# PIC32MZ2048EFM144 register map
Registers are 32-bit, access not given, reset 0x0 unless marked. A register's access mark holds for its fields unless they carry their own. Offsets are from the block's base; [hi:lo] are bit positions; {n}, {i} and the like mark numbered series; 'fields as' and 'values as' point back to an identical list.

## PORTG — PORTG peripheral
Base 0xBF860600
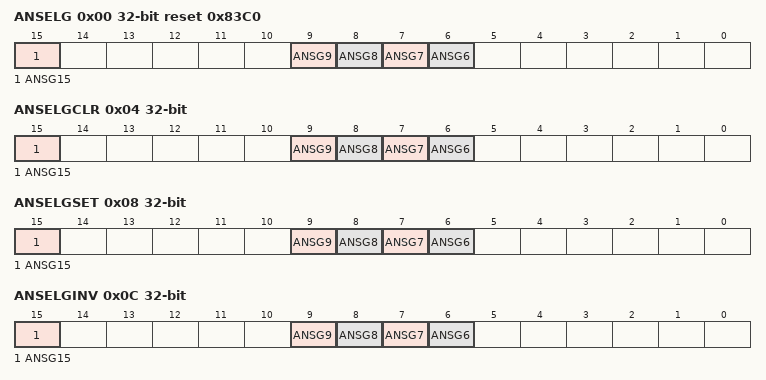
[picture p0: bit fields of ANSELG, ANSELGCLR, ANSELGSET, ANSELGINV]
0x00 ANSELG reset 0x83C0
  [15] ANSG15, [n] ANSG{n} (n=6..9)
0x04 ANSELGCLR
  [15] ANSG15, [n] ANSG{n} (n=6..9)
0x08 ANSELGSET
  [15] ANSG15, [n] ANSG{n} (n=6..9)
0x0C ANSELGINV
  [15] ANSG15, [n] ANSG{n} (n=6..9)
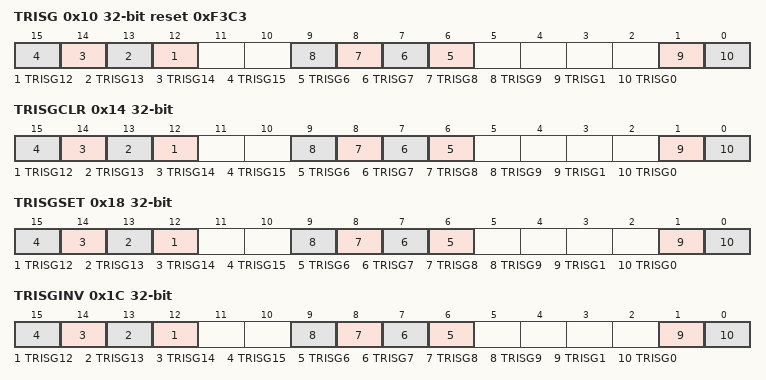
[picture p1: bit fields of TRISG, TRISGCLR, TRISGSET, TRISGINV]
0x10 TRISG reset 0xF3C3
  [n] TRISG{n} (n=12..15), [n] TRISG{n} (n=6..9), [1] TRISG1, [0] TRISG0
0x14 TRISGCLR
  fields as TRISG
0x18 TRISGSET
  fields as TRISG
0x1C TRISGINV
  fields as TRISG
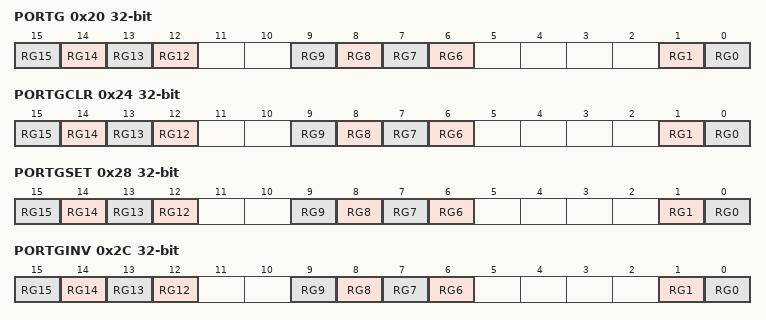
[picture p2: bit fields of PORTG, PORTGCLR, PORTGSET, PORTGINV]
0x20 PORTG
  [n] RG{n} (n=12..15), [n] RG{n} (n=6..9), [1] RG1, [0] RG0
0x24 PORTGCLR
  [n] RG{n} (n=12..15), [n] RG{n} (n=6..9), [1] RG1, [0] RG0
0x28 PORTGSET
  [n] RG{n} (n=12..15), [n] RG{n} (n=6..9), [1] RG1, [0] RG0
0x2C PORTGINV
  [n] RG{n} (n=12..15), [n] RG{n} (n=6..9), [1] RG1, [0] RG0
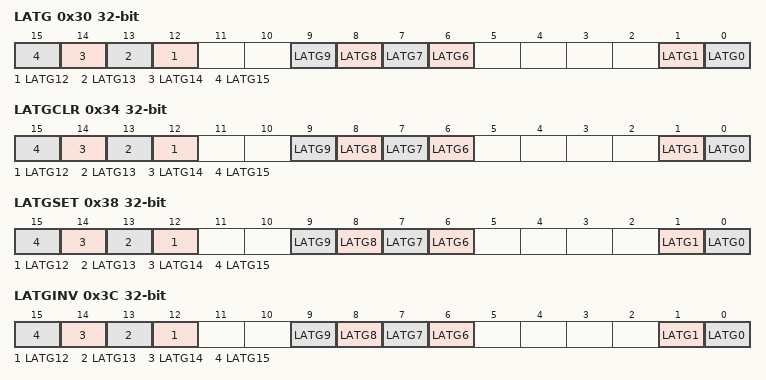
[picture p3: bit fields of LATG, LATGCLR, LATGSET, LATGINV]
0x30 LATG
  [n] LATG{n} (n=12..15), [n] LATG{n} (n=6..9), [1] LATG1, [0] LATG0
0x34 LATGCLR
  [n] LATG{n} (n=12..15), [n] LATG{n} (n=6..9), [1] LATG1, [0] LATG0
0x38 LATGSET
  [n] LATG{n} (n=12..15), [n] LATG{n} (n=6..9), [1] LATG1, [0] LATG0
0x3C LATGINV
  [n] LATG{n} (n=12..15), [n] LATG{n} (n=6..9), [1] LATG1, [0] LATG0
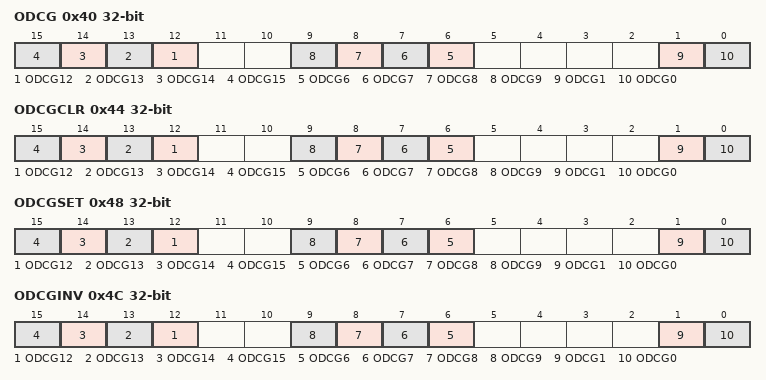
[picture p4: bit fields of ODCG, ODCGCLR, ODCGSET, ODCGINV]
0x40 ODCG
  [n] ODCG{n} (n=12..15), [n] ODCG{n} (n=6..9), [1] ODCG1, [0] ODCG0
0x44 ODCGCLR
  [n] ODCG{n} (n=12..15), [n] ODCG{n} (n=6..9), [1] ODCG1, [0] ODCG0
0x48 ODCGSET
  [n] ODCG{n} (n=12..15), [n] ODCG{n} (n=6..9), [1] ODCG1, [0] ODCG0
0x4C ODCGINV
  [n] ODCG{n} (n=12..15), [n] ODCG{n} (n=6..9), [1] ODCG1, [0] ODCG0
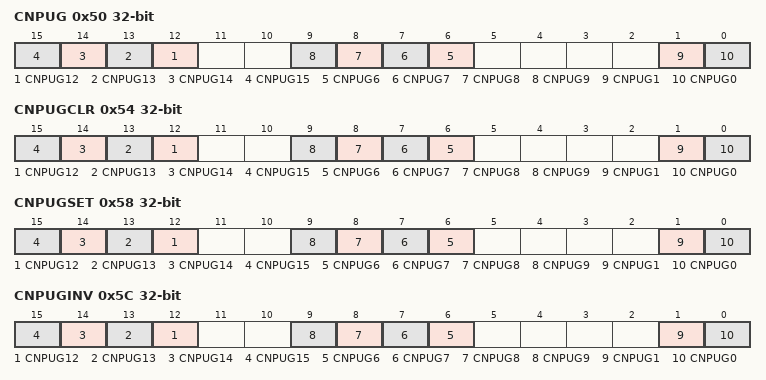
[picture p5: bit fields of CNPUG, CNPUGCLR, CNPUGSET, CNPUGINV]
0x50 CNPUG
  [n] CNPUG{n} (n=12..15), [n] CNPUG{n} (n=6..9), [1] CNPUG1, [0] CNPUG0
0x54 CNPUGCLR
  fields as CNPUG
0x58 CNPUGSET
  fields as CNPUG
0x5C CNPUGINV
  fields as CNPUG
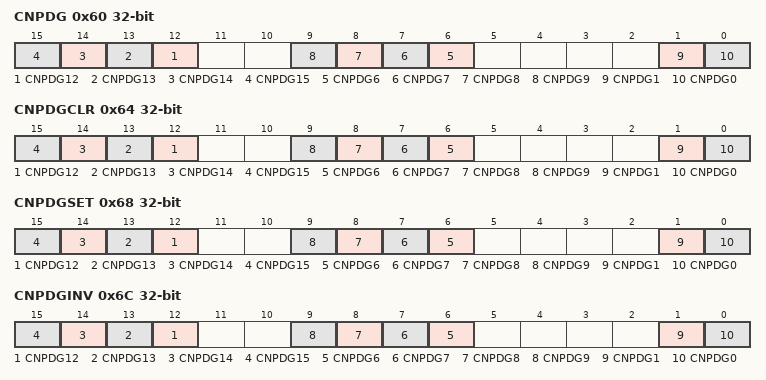
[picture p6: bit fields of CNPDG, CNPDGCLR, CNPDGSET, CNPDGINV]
0x60 CNPDG
  [n] CNPDG{n} (n=12..15), [n] CNPDG{n} (n=6..9), [1] CNPDG1, [0] CNPDG0
0x64 CNPDGCLR
  fields as CNPDG
0x68 CNPDGSET
  fields as CNPDG
0x6C CNPDGINV
  fields as CNPDG
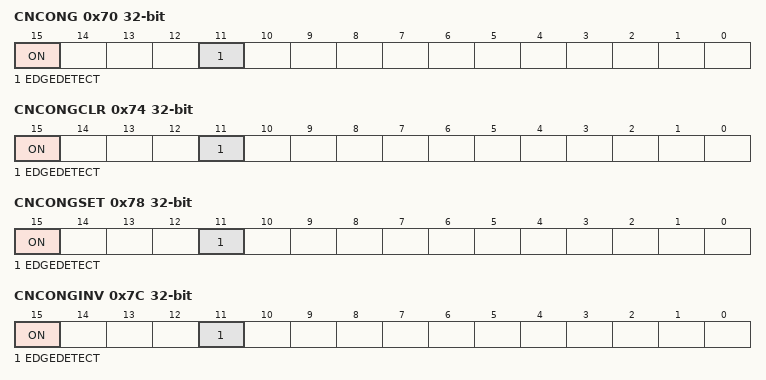
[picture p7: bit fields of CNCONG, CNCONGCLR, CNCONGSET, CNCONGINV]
0x70 CNCONG
  [15] ON, [11] EDGEDETECT
0x74 CNCONGCLR
  [15] ON, [11] EDGEDETECT
0x78 CNCONGSET
  [15] ON, [11] EDGEDETECT
0x7C CNCONGINV
  [15] ON, [11] EDGEDETECT
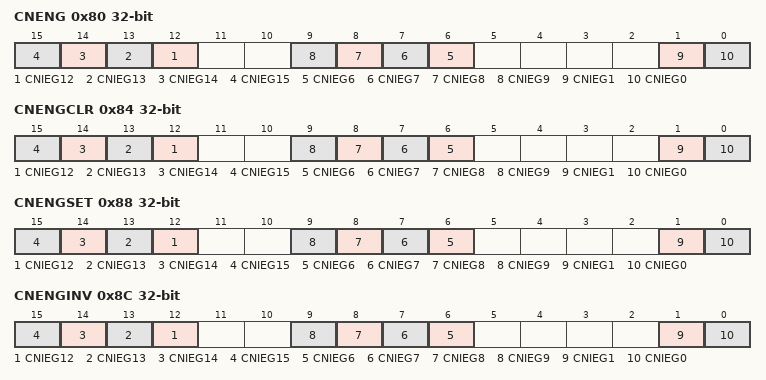
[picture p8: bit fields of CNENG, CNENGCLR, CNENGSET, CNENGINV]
0x80 CNENG
  [n] CNIEG{n} (n=12..15), [n] CNIEG{n} (n=6..9), [1] CNIEG1, [0] CNIEG0
0x84 CNENGCLR
  fields as CNENG
0x88 CNENGSET
  fields as CNENG
0x8C CNENGINV
  fields as CNENG
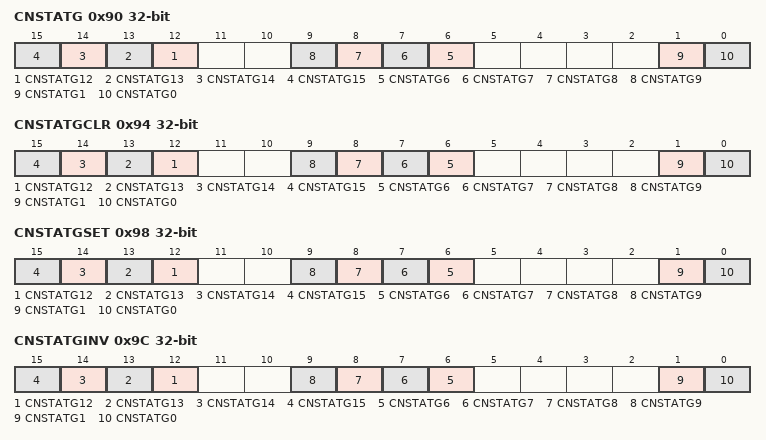
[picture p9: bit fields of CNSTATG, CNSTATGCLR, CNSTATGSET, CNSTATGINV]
0x90 CNSTATG
  [n] CNSTATG{n} (n=12..15), [n] CNSTATG{n} (n=6..9), [1] CNSTATG1, [0] CNSTATG0
0x94 CNSTATGCLR
  fields as CNSTATG
0x98 CNSTATGSET
  fields as CNSTATG
0x9C CNSTATGINV
  fields as CNSTATG
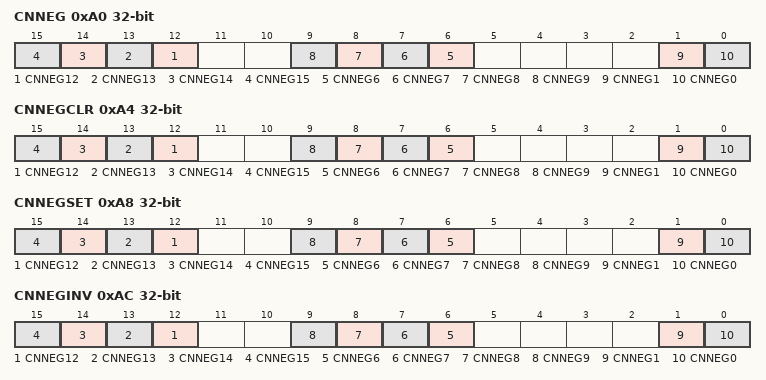
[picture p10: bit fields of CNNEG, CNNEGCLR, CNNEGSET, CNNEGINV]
0xA0 CNNEG
  [n] CNNEG{n} (n=12..15), [n] CNNEG{n} (n=6..9), [1] CNNEG1, [0] CNNEG0
0xA4 CNNEGCLR
  fields as CNNEG
0xA8 CNNEGSET
  fields as CNNEG
0xAC CNNEGINV
  fields as CNNEG
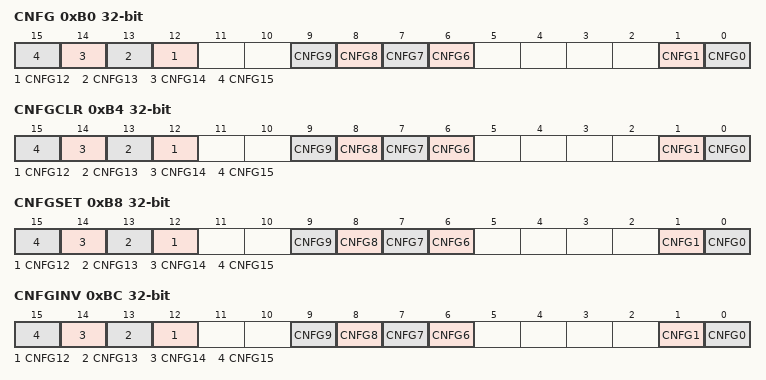
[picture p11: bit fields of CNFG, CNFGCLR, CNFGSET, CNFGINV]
0xB0 CNFG
  [n] CNFG{n} (n=12..15), [n] CNFG{n} (n=6..9), [1] CNFG1, [0] CNFG0
0xB4 CNFGCLR
  [n] CNFG{n} (n=12..15), [n] CNFG{n} (n=6..9), [1] CNFG1, [0] CNFG0
0xB8 CNFGSET
  [n] CNFG{n} (n=12..15), [n] CNFG{n} (n=6..9), [1] CNFG1, [0] CNFG0
0xBC CNFGINV
  [n] CNFG{n} (n=12..15), [n] CNFG{n} (n=6..9), [1] CNFG1, [0] CNFG0
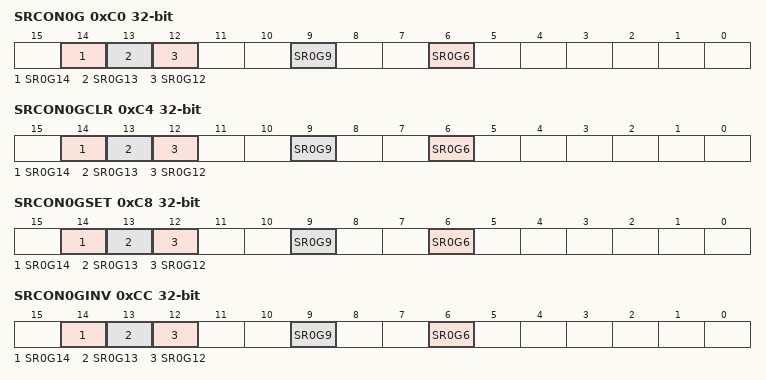
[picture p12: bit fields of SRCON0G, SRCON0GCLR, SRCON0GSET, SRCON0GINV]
0xC0 SRCON0G
  [14] SR0G14, [13] SR0G13, [12] SR0G12, [9] SR0G9, [6] SR0G6
0xC4 SRCON0GCLR
  [14] SR0G14, [13] SR0G13, [12] SR0G12, [9] SR0G9, [6] SR0G6
0xC8 SRCON0GSET
  [14] SR0G14, [13] SR0G13, [12] SR0G12, [9] SR0G9, [6] SR0G6
0xCC SRCON0GINV
  [14] SR0G14, [13] SR0G13, [12] SR0G12, [9] SR0G9, [6] SR0G6
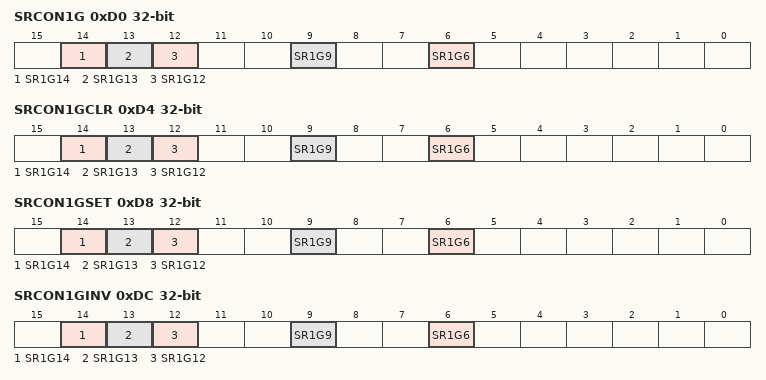
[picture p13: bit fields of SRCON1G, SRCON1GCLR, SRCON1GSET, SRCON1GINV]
0xD0 SRCON1G
  [14] SR1G14, [13] SR1G13, [12] SR1G12, [9] SR1G9, [6] SR1G6
0xD4 SRCON1GCLR
  [14] SR1G14, [13] SR1G13, [12] SR1G12, [9] SR1G9, [6] SR1G6
0xD8 SRCON1GSET
  [14] SR1G14, [13] SR1G13, [12] SR1G12, [9] SR1G9, [6] SR1G6
0xDC SRCON1GINV
  [14] SR1G14, [13] SR1G13, [12] SR1G12, [9] SR1G9, [6] SR1G6

## PORTH — PORTH peripheral
Base 0xBF860700
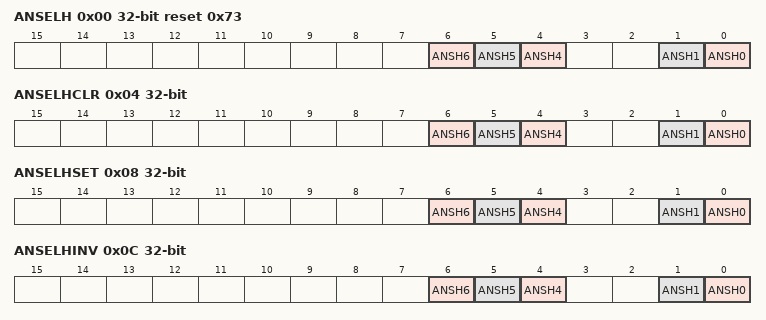
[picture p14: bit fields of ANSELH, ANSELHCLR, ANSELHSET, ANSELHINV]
0x00 ANSELH reset 0x73
  [6] ANSH6, [5] ANSH5, [4] ANSH4, [1] ANSH1, [0] ANSH0
0x04 ANSELHCLR
  [6] ANSH6, [5] ANSH5, [4] ANSH4, [1] ANSH1, [0] ANSH0
0x08 ANSELHSET
  [6] ANSH6, [5] ANSH5, [4] ANSH4, [1] ANSH1, [0] ANSH0
0x0C ANSELHINV
  [6] ANSH6, [5] ANSH5, [4] ANSH4, [1] ANSH1, [0] ANSH0
0x10 TRISH reset 0xFFFF
  [n] TRISH{n} (n=0..15)
0x14 TRISHCLR
  [n] TRISH{n} (n=0..15)
0x18 TRISHSET
  [n] TRISH{n} (n=0..15)
0x1C TRISHINV
  [n] TRISH{n} (n=0..15)
0x20 PORTH
  [n] RH{n} (n=0..15)
0x24 PORTHCLR
  [n] RH{n} (n=0..15)
0x28 PORTHSET
  [n] RH{n} (n=0..15)
0x2C PORTHINV
  [n] RH{n} (n=0..15)
0x30 LATH
  [n] LATH{n} (n=0..15)
0x34 LATHCLR
  [n] LATH{n} (n=0..15)
0x38 LATHSET
  [n] LATH{n} (n=0..15)
0x3C LATHINV
  [n] LATH{n} (n=0..15)
0x40 ODCH
  [n] ODCH{n} (n=0..15)
0x44 ODCHCLR
  [n] ODCH{n} (n=0..15)
0x48 ODCHSET
  [n] ODCH{n} (n=0..15)
0x4C ODCHINV
  [n] ODCH{n} (n=0..15)
0x50 CNPUH
  [n] CNPUH{n} (n=0..15)
0x54 CNPUHCLR
  [n] CNPUH{n} (n=0..15)
0x58 CNPUHSET
  [n] CNPUH{n} (n=0..15)
0x5C CNPUHINV
  [n] CNPUH{n} (n=0..15)
0x60 CNPDH
  [n] CNPDH{n} (n=0..15)
0x64 CNPDHCLR
  [n] CNPDH{n} (n=0..15)
0x68 CNPDHSET
  [n] CNPDH{n} (n=0..15)
0x6C CNPDHINV
  [n] CNPDH{n} (n=0..15)
0x70 CNCONH
  [15] ON, [11] EDGEDETECT
0x74 CNCONHCLR
  [15] ON, [11] EDGEDETECT
0x78 CNCONHSET
  [15] ON, [11] EDGEDETECT
0x7C CNCONHINV
  [15] ON, [11] EDGEDETECT
0x80 CNENH
  [n] CNIEH{n} (n=0..15)
0x84 CNENHCLR
  [n] CNIEH{n} (n=0..15)
0x88 CNENHSET
  [n] CNIEH{n} (n=0..15)
0x8C CNENHINV
  [n] CNIEH{n} (n=0..15)
0x90 CNSTATH
  [n] CNSTATH{n} (n=0..15)
0x94 CNSTATHCLR
  [n] CNSTATH{n} (n=0..15)
0x98 CNSTATHSET
  [n] CNSTATH{n} (n=0..15)
0x9C CNSTATHINV
  [n] CNSTATH{n} (n=0..15)
0xA0 CNNEH
  [n] CNNEH{n} (n=0..15)
0xA4 CNNEHCLR
  [n] CNNEH{n} (n=0..15)
0xA8 CNNEHSET
  [n] CNNEH{n} (n=0..15)
0xAC CNNEHINV
  [n] CNNEH{n} (n=0..15)
0xB0 CNFH
  [n] CNFH{n} (n=0..15)
0xB4 CNFHCLR
  [n] CNFH{n} (n=0..15)
0xB8 CNFHSET
  [n] CNFH{n} (n=0..15)
0xBC CNFHINV
  [n] CNFH{n} (n=0..15)
